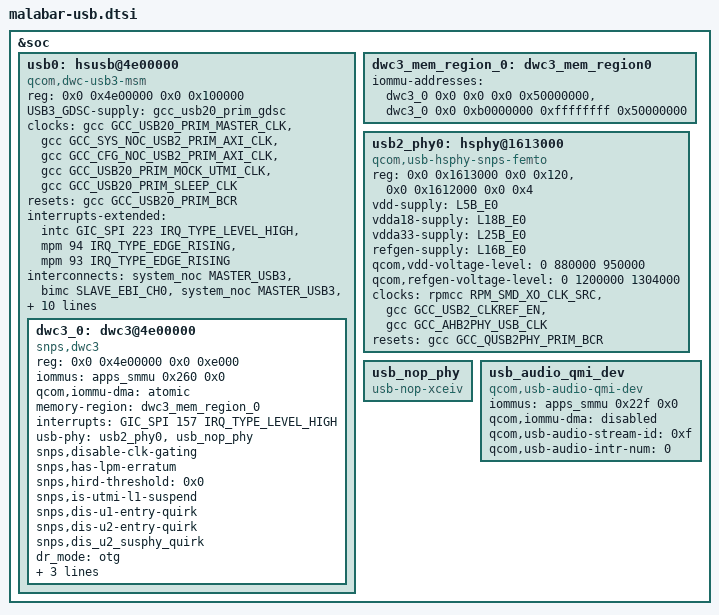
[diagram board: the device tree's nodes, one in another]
// SPDX-License-Identifier: BSD-3-Clause
/*
 * Copyright (c) Qualcomm Technologies, Inc. and/or its subsidiaries.
 */

#include <dt-bindings/clock/qcom,malabar-gcc.h>

&soc {
	usb0: hsusb@4e00000 {
		compatible = "qcom,dwc-usb3-msm";
		reg = <0x0 0x4e00000 0x0 0x100000>;
		reg-names = "core_base";

		#address-cells = <2>;
		#size-cells = <2>;
		ranges;

		USB3_GDSC-supply = <&gcc_usb20_prim_gdsc>;
		clocks = <&gcc GCC_USB20_PRIM_MASTER_CLK>,
			<&gcc GCC_SYS_NOC_USB2_PRIM_AXI_CLK>,
			<&gcc GCC_CFG_NOC_USB2_PRIM_AXI_CLK>,
			<&gcc GCC_USB20_PRIM_MOCK_UTMI_CLK>,
			<&gcc GCC_USB20_PRIM_SLEEP_CLK>;
		clock-names = "core_clk", "iface_clk", "bus_aggr_clk",
					"utmi_clk", "sleep_clk";

		resets = <&gcc GCC_USB20_PRIM_BCR>;
		reset-names = "core_reset";

		interrupts-extended = <&intc GIC_SPI 223 IRQ_TYPE_LEVEL_HIGH>,
				<&mpm 94 IRQ_TYPE_EDGE_RISING>,
				<&mpm 93 IRQ_TYPE_EDGE_RISING>;
		interrupt-names = "pwr_event_irq", "dp_hs_phy_irq",
					"dm_hs_phy_irq";

		interconnect-names = "usb-ddr", "usb-ipa", "ddr-usb";
		interconnects = <&system_noc MASTER_USB3 &bimc SLAVE_EBI_CH0>,
				<&system_noc MASTER_USB3 &config_noc SLAVE_IPA_CFG>,
				<&bimc MASTER_AMPSS_M0 &config_noc SLAVE_USB3>;

		qcom,dis-sending-cm-l1-quirk;
		qcom,core-clk-rate = <66666667>;
		qcom,default-bus-vote = <2>; /* use svs bus voting */
		extcon = <&eud>;

		qcom,num-gsi-evt-buffs = <0x3>;
		qcom,gsi-reg-offset =
			<0x0fc /* GSI_GENERAL_CFG */
			0x110 /* GSI_DBL_ADDR_L */
			0x120 /* GSI_DBL_ADDR_H */
			0x130 /* GSI_RING_BASE_ADDR_L */
			0x144 /* GSI_RING_BASE_ADDR_H */
			0x1a4>; /* GSI_IF_STS */

		/*
		 * Establish dependency on smmu driver so that depopulate path of
		 * deferred probe doesn't run into existing bug in smmu driver.
		 */
		dummy-supply = <&apps_smmu>;

		dwc3_0: dwc3@4e00000 {
			compatible = "snps,dwc3";
			reg = <0x0 0x4e00000 0x0 0xe000>;

			iommus = <&apps_smmu 0x260 0x0>;
			qcom,iommu-dma = "atomic";
			memory-region = <&dwc3_mem_region_0>;

			interrupts = <GIC_SPI 157 IRQ_TYPE_LEVEL_HIGH>;
			usb-phy = <&usb2_phy0>, <&usb_nop_phy>;
			snps,disable-clk-gating;
			snps,has-lpm-erratum;
			snps,hird-threshold = /bits/ 8 <0x0>;
			snps,is-utmi-l1-suspend;
			snps,dis-u1-entry-quirk;
			snps,dis-u2-entry-quirk;
			snps,dis_u2_susphy_quirk;
			dr_mode = "otg";
			maximum-speed = "high-speed";
			usb-role-switch;
			imod-interval-ns = <160000>;
		};
	};

	dwc3_mem_region_0: dwc3_mem_region0 {
		iommu-addresses = <&dwc3_0 0x0 0x0 0x0 0x50000000>,
				<&dwc3_0 0x0 0xb0000000 0xffffffff 0x50000000>;
	};

	/* USB port related High Speed PHY */
	usb2_phy0: hsphy@1613000 {
		compatible = "qcom,usb-hsphy-snps-femto";
		reg = <0x0 0x1613000 0x0 0x120>,
			<0x0 0x1612000 0x0 0x4>;
		reg-names = "hsusb_phy_base",
				"eud_enable_reg";

		vdd-supply = <&L5B_E0>;
		vdda18-supply = <&L18B_E0>;
		vdda33-supply = <&L25B_E0>;
		refgen-supply = <&L16B_E0>;

		qcom,vdd-voltage-level = <0 880000 950000>;
		qcom,refgen-voltage-level = <0 1200000 1304000>;

		clocks = <&rpmcc RPM_SMD_XO_CLK_SRC>,
			<&gcc GCC_USB2_CLKREF_EN>,
			<&gcc GCC_AHB2PHY_USB_CLK>;
		clock-names = "ref_clk_src", "ref_clk", "cfg_ahb_clk";

		resets = <&gcc GCC_QUSB2PHY_PRIM_BCR>;
		reset-names = "phy_reset";
	};

	usb_nop_phy: usb_nop_phy {
		compatible = "usb-nop-xceiv";
	};

	usb_audio_qmi_dev {
		compatible = "qcom,usb-audio-qmi-dev";
		iommus = <&apps_smmu 0x22f 0x0>;
		qcom,iommu-dma = "disabled";
		qcom,usb-audio-stream-id = <0xf>;
		qcom,usb-audio-intr-num = <0>;
	};
};
